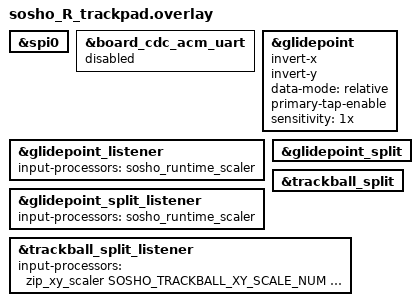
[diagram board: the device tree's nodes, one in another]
#include "sosho_R.dtsi"

/* Alternate central variant: RIGHT is the central trackpad side.
 * The right-side module is rotated relative to the left-side module, so
 * both axes are inverted here. Use the official relative Pinnacle path;
 * it keeps movement and primary tap independent of absolute coordinates. */
&spi0 { status = "okay"; };

/* Expose one unambiguous CDC-ACM endpoint for the web editor. */
&board_cdc_acm_uart { status = "disabled"; };

&glidepoint {
    status = "okay";
    invert-x;
    invert-y;
    data-mode = "relative";
    primary-tap-enable;
    sensitivity = "1x";
};
&glidepoint_listener {
    status = "okay";
    input-processors = <&sosho_runtime_scaler>;
};

/* The central can also receive the left peripheral's trackpad input. */
&glidepoint_split { status = "okay"; };
&glidepoint_split_listener {
    status = "okay";
    /* A left peripheral keeps its own left-side orientation and uses the
     * same relative input path as the normal trackball central profile. */
    input-processors = <&sosho_runtime_scaler>;
};

/* Keep the alternate left-trackball combination available. */
&trackball_split { status = "okay"; };
&trackball_split_listener {
    status = "okay";
    input-processors = <&zip_xy_scaler SOSHO_TRACKBALL_XY_SCALE_NUM SOSHO_TRACKBALL_XY_SCALE_DEN>;
};
